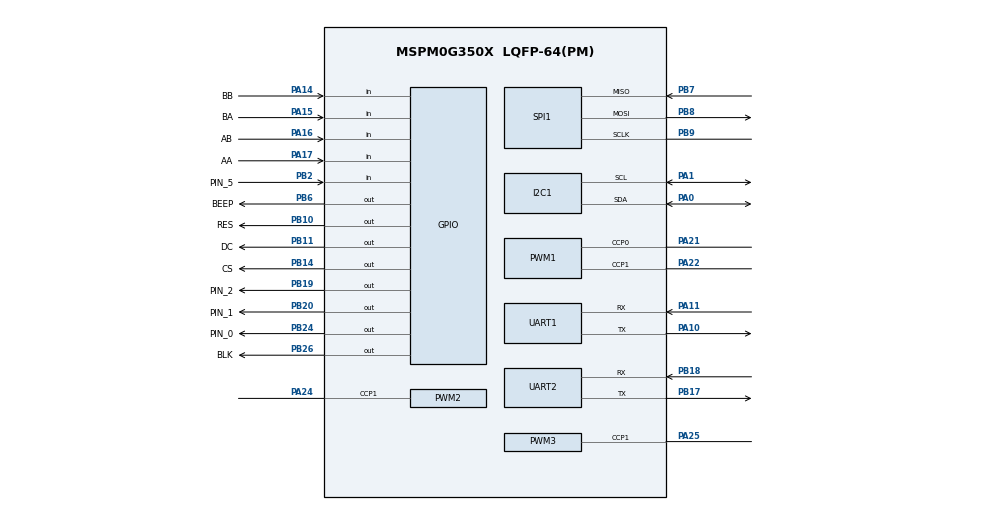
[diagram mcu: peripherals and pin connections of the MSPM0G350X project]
/**
 * @cliArgs --device "MSPM0G350X" --part "Default" --package "LQFP-64(PM)" --product "mspm0_sdk@2.10.00.04"
 * @versions {"tool":"1.26.2+4477"}
 */

/**
 * Import the modules used in this configuration.
 */
const ADC12   = scripting.addModule("/ti/driverlib/ADC12", {}, false);
const ADC121  = ADC12.addInstance();
const GPIO    = scripting.addModule("/ti/driverlib/GPIO", {}, false);
const GPIO1   = GPIO.addInstance();
const GPIO2   = GPIO.addInstance();
const GPIO3   = GPIO.addInstance();
const GPIO4   = GPIO.addInstance();
const I2C     = scripting.addModule("/ti/driverlib/I2C", {}, false);
const I2C1    = I2C.addInstance();
const PWM     = scripting.addModule("/ti/driverlib/PWM", {}, false);
const PWM1    = PWM.addInstance();
const PWM2    = PWM.addInstance();
const PWM3    = PWM.addInstance();
const SPI     = scripting.addModule("/ti/driverlib/SPI", {}, false);
const SPI1    = SPI.addInstance();
const SYSCTL  = scripting.addModule("/ti/driverlib/SYSCTL");
const SYSTICK = scripting.addModule("/ti/driverlib/SYSTICK");
const TIMER   = scripting.addModule("/ti/driverlib/TIMER", {}, false);
const TIMER1  = TIMER.addInstance();
const UART    = scripting.addModule("/ti/driverlib/UART", {}, false);
const UART1   = UART.addInstance();
const UART2   = UART.addInstance();

/**
 * Write custom configuration values to the imported modules.
 */
ADC121.$name               = "ADC12_0";
ADC121.repeatMode          = true;
ADC121.adcMem0_name        = "ADC_CH0";
ADC121.sampClkDiv          = "DL_ADC12_CLOCK_DIVIDE_8";
ADC121.enabledInterrupts   = ["DL_ADC12_INTERRUPT_MEM0_RESULT_LOADED"];
ADC121.sampleTime0         = "2us";
ADC121.peripheral.$assign  = "ADC0";
ADC121.adcPin0Config.$name = "ti_driverlib_gpio_GPIOPinGeneric0";

const Board = scripting.addModule("/ti/driverlib/Board", {}, false);

GPIO1.$name                              = "Gray_Address";
GPIO1.associatedPins.create(3);
GPIO1.associatedPins[0].$name            = "PIN_0";
GPIO1.associatedPins[0].pin.$assign      = "PB24";
GPIO1.associatedPins[1].$name            = "PIN_1";
GPIO1.associatedPins[1].pin.$assign      = "PB20";
GPIO1.associatedPins[2].$name            = "PIN_2";
GPIO1.associatedPins[2].internalResistor = "PULL_UP";
GPIO1.associatedPins[2].pin.$assign      = "PB19";

GPIO2.$name                              = "encoder";
GPIO2.associatedPins.create(4);
GPIO2.associatedPins[0].$name            = "AA";
GPIO2.associatedPins[0].direction        = "INPUT";
GPIO2.associatedPins[0].internalResistor = "PULL_DOWN";
GPIO2.associatedPins[0].interruptEn      = true;
GPIO2.associatedPins[0].polarity         = "RISE";
GPIO2.associatedPins[0].pin.$assign      = "PA17";
GPIO2.associatedPins[1].$name            = "AB";
GPIO2.associatedPins[1].direction        = "INPUT";
GPIO2.associatedPins[1].internalResistor = "PULL_DOWN";
GPIO2.associatedPins[1].pin.$assign      = "PA16";
GPIO2.associatedPins[2].$name            = "BA";
GPIO2.associatedPins[2].direction        = "INPUT";
GPIO2.associatedPins[2].internalResistor = "PULL_DOWN";
GPIO2.associatedPins[2].interruptEn      = true;
GPIO2.associatedPins[2].polarity         = "RISE";
GPIO2.associatedPins[2].pin.$assign      = "PA15";
GPIO2.associatedPins[3].$name            = "BB";
GPIO2.associatedPins[3].direction        = "INPUT";
GPIO2.associatedPins[3].internalResistor = "PULL_DOWN";
GPIO2.associatedPins[3].pin.$assign      = "PA14";

GPIO3.$name                              = "GPIO_GRP_0";
GPIO3.associatedPins.create(4);
GPIO3.associatedPins[0].$name            = "BEEP";
GPIO3.associatedPins[0].initialValue     = "SET";
GPIO3.associatedPins[0].pin.$assign      = "PB6";
GPIO3.associatedPins[1].$name            = "PIN_3";
GPIO3.associatedPins[1].direction        = "INPUT";
GPIO3.associatedPins[1].internalResistor = "PULL_UP";
GPIO3.associatedPins[2].$name            = "PIN_4";
GPIO3.associatedPins[2].direction        = "INPUT";
GPIO3.associatedPins[2].internalResistor = "PULL_UP";
GPIO3.associatedPins[3].$name            = "PIN_5";
GPIO3.associatedPins[3].direction        = "INPUT";
GPIO3.associatedPins[3].internalResistor = "PULL_UP";
GPIO3.associatedPins[3].pin.$assign      = "PB2";

GPIO4.$name                         = "LCD";
GPIO4.associatedPins.create(4);
GPIO4.associatedPins[0].$name       = "RES";
GPIO4.associatedPins[0].pin.$assign = "PB10";
GPIO4.associatedPins[1].$name       = "DC";
GPIO4.associatedPins[1].pin.$assign = "PB11";
GPIO4.associatedPins[2].$name       = "CS";
GPIO4.associatedPins[2].pin.$assign = "PB14";
GPIO4.associatedPins[3].$name       = "BLK";
GPIO4.associatedPins[3].pin.$assign = "PB26";

I2C1.basicEnableController             = true;
I2C1.basicControllerBusSpeed           = 400000;
I2C1.$name                             = "I2C_MPU";
I2C1.advAnalogGlitchFilter             = "DISABLED";
I2C1.peripheral.sdaPin.$assign         = "PA0";
I2C1.peripheral.sclPin.$assign         = "PA1";
I2C1.sdaPinConfig.hideOutputInversion  = scripting.forceWrite(false);
I2C1.sdaPinConfig.onlyInternalResistor = scripting.forceWrite(false);
I2C1.sdaPinConfig.passedPeripheralType = scripting.forceWrite("Digital");
I2C1.sdaPinConfig.enableConfig         = true;
I2C1.sdaPinConfig.$name                = "ti_driverlib_gpio_GPIOPinGeneric5";
I2C1.sclPinConfig.hideOutputInversion  = scripting.forceWrite(false);
I2C1.sclPinConfig.onlyInternalResistor = scripting.forceWrite(false);
I2C1.sclPinConfig.passedPeripheralType = scripting.forceWrite("Digital");
I2C1.sclPinConfig.enableConfig         = true;
I2C1.sclPinConfig.$name                = "ti_driverlib_gpio_GPIOPinGeneric6";

PWM1.$name                      = "PWM_0";
PWM1.clockDivider               = 8;
PWM1.peripheral.ccp0Pin.$assign = "PA21";
PWM1.peripheral.ccp1Pin.$assign = "PA22";
PWM1.PWM_CHANNEL_0.$name        = "ti_driverlib_pwm_PWMTimerCC0";
PWM1.PWM_CHANNEL_1.$name        = "ti_driverlib_pwm_PWMTimerCC1";
PWM1.ccp0PinConfig.$name        = "ti_driverlib_gpio_GPIOPinGeneric3";
PWM1.ccp1PinConfig.$name        = "ti_driverlib_gpio_GPIOPinGeneric4";

PWM2.$name                      = "PWM_1";
PWM2.clockDivider               = 8;
PWM2.peripheral.ccp1Pin.$assign = "PA24";
PWM2.PWM_CHANNEL_0.$name        = "ti_driverlib_pwm_PWMTimerCC2";
PWM2.PWM_CHANNEL_1.$name        = "ti_driverlib_pwm_PWMTimerCC3";
PWM2.ccp0PinConfig.$name        = "ti_driverlib_gpio_GPIOPinGeneric11";
PWM2.ccp1PinConfig.$name        = "ti_driverlib_gpio_GPIOPinGeneric12";

PWM3.$name                      = "PWM_2";
PWM3.clockDivider               = 8;
PWM3.peripheral.ccp1Pin.$assign = "PA25";
PWM3.PWM_CHANNEL_0.$name        = "ti_driverlib_pwm_PWMTimerCC4";
PWM3.PWM_CHANNEL_1.$name        = "ti_driverlib_pwm_PWMTimerCC5";
PWM3.ccp0PinConfig.$name        = "ti_driverlib_gpio_GPIOPinGeneric13";
PWM3.ccp1PinConfig.$name        = "ti_driverlib_gpio_GPIOPinGeneric14";

SPI1.$name                              = "SPI_LCD";
SPI1.peripheral.sclkPin.$assign         = "PB9";
SPI1.peripheral.mosiPin.$assign         = "PB8";
SPI1.peripheral.misoPin.$assign         = "PB7";
SPI1.sclkPinConfig.direction            = scripting.forceWrite("OUTPUT");
SPI1.sclkPinConfig.onlyInternalResistor = scripting.forceWrite(false);
SPI1.sclkPinConfig.passedPeripheralType = scripting.forceWrite("Digital");
SPI1.sclkPinConfig.$name                = "ti_driverlib_gpio_GPIOPinGeneric7";
SPI1.mosiPinConfig.direction            = scripting.forceWrite("OUTPUT");
SPI1.mosiPinConfig.hideOutputInversion  = scripting.forceWrite(false);
SPI1.mosiPinConfig.onlyInternalResistor = scripting.forceWrite(false);
SPI1.mosiPinConfig.passedPeripheralType = scripting.forceWrite("Digital");
SPI1.mosiPinConfig.$name                = "ti_driverlib_gpio_GPIOPinGeneric8";
SPI1.misoPinConfig.onlyInternalResistor = scripting.forceWrite(false);
SPI1.misoPinConfig.passedPeripheralType = scripting.forceWrite("Digital");
SPI1.misoPinConfig.$name                = "ti_driverlib_gpio_GPIOPinGeneric9";
SPI1.cs0PinConfig.direction             = scripting.forceWrite("OUTPUT");
SPI1.cs0PinConfig.hideOutputInversion   = scripting.forceWrite(false);
SPI1.cs0PinConfig.onlyInternalResistor  = scripting.forceWrite(false);
SPI1.cs0PinConfig.passedPeripheralType  = scripting.forceWrite("Digital");
SPI1.cs0PinConfig.$name                 = "ti_driverlib_gpio_GPIOPinGeneric10";

SYSCTL.forceDefaultClkConfig = true;
SYSCTL.clockTreeEn           = true;

SYSTICK.periodEnable    = true;
SYSTICK.interruptEnable = true;
SYSTICK.systickEnable   = true;
SYSTICK.period          = 32000;

TIMER1.$name            = "TIMER_0";
TIMER1.timerClkDiv      = 8;
TIMER1.timerClkPrescale = 8;
TIMER1.timerStartTimer  = true;
TIMER1.interrupts       = ["LOAD"];
TIMER1.timerMode        = "PERIODIC_UP";
TIMER1.timerPeriod      = "10ms";

UART1.$name                    = "UART_0";
UART1.targetBaudRate           = 115200;
UART1.peripheral.rxPin.$assign = "PA11";
UART1.peripheral.txPin.$assign = "PA10";
UART1.txPinConfig.$name        = "ti_driverlib_gpio_GPIOPinGeneric1";
UART1.rxPinConfig.$name        = "ti_driverlib_gpio_GPIOPinGeneric2";

UART2.$name                            = "UART2";
UART2.targetBaudRate                   = 115200;
UART2.peripheral.$assign               = "UART2";
UART2.peripheral.rxPin.$assign         = "PB18";
UART2.peripheral.txPin.$assign         = "PB17";
UART2.txPinConfig.$name                = "ti_driverlib_gpio_GPIOPinGeneric15";
UART2.txPinConfig.direction            = scripting.forceWrite("OUTPUT");
UART2.txPinConfig.hideOutputInversion  = scripting.forceWrite(false);
UART2.txPinConfig.onlyInternalResistor = scripting.forceWrite(false);
UART2.txPinConfig.passedPeripheralType = scripting.forceWrite("Digital");
UART2.rxPinConfig.$name                = "ti_driverlib_gpio_GPIOPinGeneric16";
UART2.rxPinConfig.hideOutputInversion  = scripting.forceWrite(false);
UART2.rxPinConfig.onlyInternalResistor = scripting.forceWrite(false);
UART2.rxPinConfig.passedPeripheralType = scripting.forceWrite("Digital");

/**
 * Pinmux solution for unlocked pins/peripherals. This ensures that minor changes to the automatic solver in a future
 * version of the tool will not impact the pinmux you originally saw.  These lines can be completely deleted in order to
 * re-solve from scratch.
 */
ADC121.peripheral.adcPin0.$suggestSolution   = "PA27";
Board.peripheral.$suggestSolution            = "DEBUGSS";
Board.peripheral.swclkPin.$suggestSolution   = "PA20";
Board.peripheral.swdioPin.$suggestSolution   = "PA19";
GPIO3.associatedPins[1].pin.$suggestSolution = "PB16";
GPIO3.associatedPins[2].pin.$suggestSolution = "PB15";
I2C1.peripheral.$suggestSolution             = "I2C0";
PWM1.peripheral.$suggestSolution             = "TIMG6";
PWM2.peripheral.$suggestSolution             = "TIMA1";
PWM2.peripheral.ccp0Pin.$suggestSolution     = "PA28";
PWM3.peripheral.$suggestSolution             = "TIMG12";
PWM3.peripheral.ccp0Pin.$suggestSolution     = "PB13";
SPI1.peripheral.$suggestSolution             = "SPI1";
SPI1.peripheral.cs0Pin.$suggestSolution      = "PA2";
TIMER1.peripheral.$suggestSolution           = "TIMA0";
UART1.peripheral.$suggestSolution            = "UART0";
